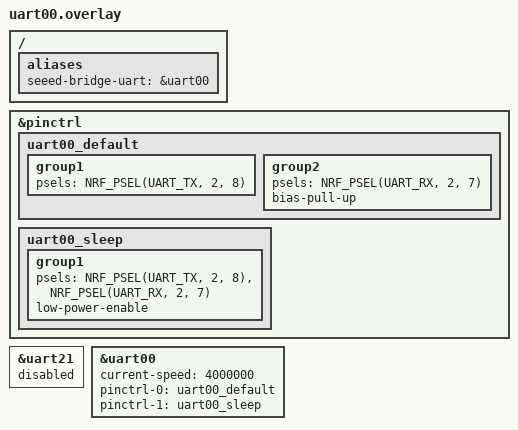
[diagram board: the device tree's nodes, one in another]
/*
 * Optional 4 Mbaud host path.
 *
 * nRF54L15 UARTE00 can use P2.07 RX / P2.08 TX, which are XIAO D7/D6 on the
 * exposed UART. They are not connected to the SAMD11 USB-UART, so this build
 * requires an external 3.3 V USB-UART adapter wired to D7 (adapter TX),
 * D6 (adapter RX), and GND. Do not connect 5 V logic.
 *
 * UART21 must be disabled so it does not claim the same pins. The radio SPI
 * uses different P2 pins and is not part of this loopback build.
 */
/ {
	aliases {
		seeed-bridge-uart = &uart00;
	};
};

&pinctrl {
	uart00_default: uart00_default {
		group1 {
			psels = <NRF_PSEL(UART_TX, 2, 8)>;
		};
		group2 {
			psels = <NRF_PSEL(UART_RX, 2, 7)>;
			bias-pull-up;
		};
	};

	uart00_sleep: uart00_sleep {
		group1 {
			psels = <NRF_PSEL(UART_TX, 2, 8)>,
				<NRF_PSEL(UART_RX, 2, 7)>;
			low-power-enable;
		};
	};
};

&uart21 {
	status = "disabled";
};

&uart00 {
	status = "okay";
	current-speed = <4000000>;
	pinctrl-0 = <&uart00_default>;
	pinctrl-1 = <&uart00_sleep>;
	pinctrl-names = "default", "sleep";
};
